# STM32N647 register map
File version: 1.0
CPU: CM55 r0p1, little endian, no MPU, FPU, vendor SysTick, 8 interrupt priority bits
Registers are 32-bit, read-write, reset 0x0 unless marked. A register's access mark holds for its fields unless they carry their own. Offsets are from the block's base; [hi:lo] are bit positions.

## RAMCFG — SRAM configuration controller
Base 0x42023000
Same registers: RAMCFG_S 0x52023000
0x00 AXISRAM1CR — RAMCFG AXISRAM1 control register
  [8] SRAMER — SRAM erase.
0x08 AXISRAM1ISR ro — RAMCFG AXISRAM1 interrupt status register
  [8] SRAMBUSY — SRAM busy with erase operation
0x28 AXISRAM1ERKEYR wo — RAMCFG AXISRAM1 erase key register
  [7:0] ERASEKEY — Erase write protection key
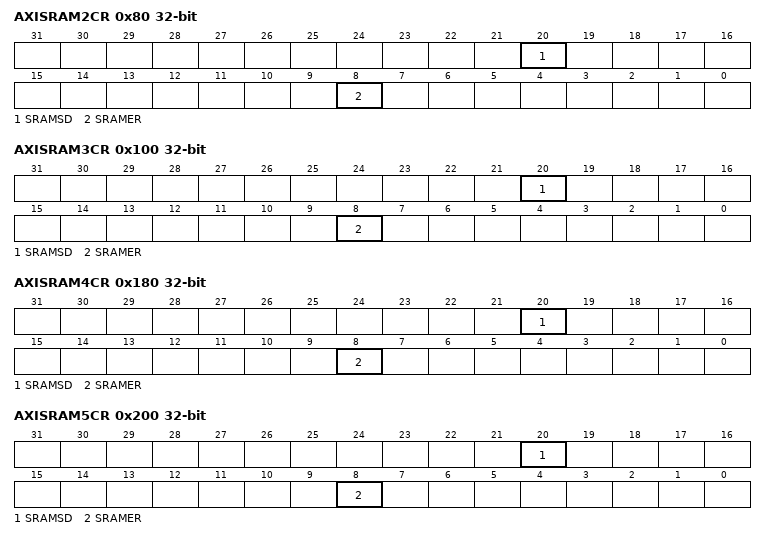
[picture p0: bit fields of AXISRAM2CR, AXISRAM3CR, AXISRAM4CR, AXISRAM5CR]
0x80 AXISRAM2CR — RAMCFG AXISRAM2 control register
  [20] SRAMSD — Shutdown AXISRAMx
  [8] SRAMER — SRAM erase
0x88 AXISRAM2ISR ro — RAMCFG AXISRAM2 interrupt status register
  [8] SRAMBUSY — SRAM busy with erase operation
0xA8 AXISRAM2ERKEYR wo — RAMCFG AXISRAM2 erase key register
  [7:0] ERASEKEY — Erase write protection key
0x100 AXISRAM3CR — RAMCFG AXISRAM3 control register
  [20] SRAMSD — Shutdown AXISRAMx
  [8] SRAMER — SRAM erase
0x108 AXISRAM3ISR ro — RAMCFG AXISRAM3 interrupt status register
  [8] SRAMBUSY — SRAM busy with erase operation
0x128 AXISRAM3ERKEYR wo — RAMCFG AXISRAM3 erase key register
  [7:0] ERASEKEY — Erase write protection key
0x180 AXISRAM4CR — RAMCFG AXISRAM4 control register
  [20] SRAMSD — Shutdown AXISRAMx
  [8] SRAMER — SRAM erase
0x188 AXISRAM4ISR ro — RAMCFG AXISRAM4 interrupt status register
  [8] SRAMBUSY — SRAM busy with erase operation
0x1A8 AXISRAM4ERKEYR wo — RAMCFG AXISRAM4 erase key register
  [7:0] ERASEKEY — Erase write protection key
0x200 AXISRAM5CR — RAMCFG AXISRAM5 control register
  [20] SRAMSD — Shutdown AXISRAMx
  [8] SRAMER — SRAM erase
0x208 AXISRAM5ISR ro — RAMCFG AXISRAM5 interrupt status register
  [8] SRAMBUSY — SRAM busy with erase operation
0x228 AXISRAM5ERKEYR wo — RAMCFG AXISRAM5 erase key register
  [7:0] ERASEKEY — Erase write protection key
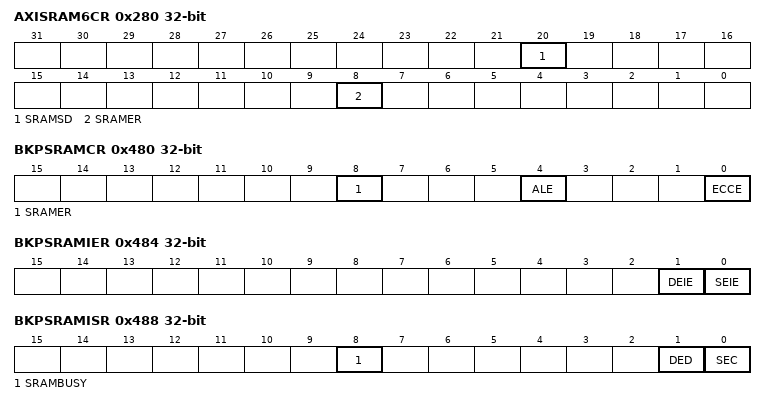
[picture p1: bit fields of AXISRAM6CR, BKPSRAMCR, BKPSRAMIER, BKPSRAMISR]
0x280 AXISRAM6CR — RAMCFG AXISRAM6 control register
  [20] SRAMSD — Shutdown AXISRAMx
  [8] SRAMER — SRAM erase
0x288 AXISRAM6ISR ro — RAMCFG AXISRAM6 interrupt status register
  [8] SRAMBUSY — SRAM busy with erase operation
0x2A8 AXISRAM6ERKEYR wo — RAMCFG AXISRAM6 erase key register
  [7:0] ERASEKEY — Erase write protection key
0x300 AHBSRAM1CR — RAMCFG AHBSRAM1 control register
  [8] SRAMER — SRAM erase
0x308 AHBSRAM1ISR ro — RAMCFG AHBSRAM1 interrupt status register
  [8] SRAMBUSY — SRAM busy with erase operation
0x328 AHBSRAM1ERKEYR wo — RAMCFG AHBSRAM1 erase key register
  [7:0] ERASEKEY — Erase write protection key
0x380 AHBSRAM2CR — RAMCFG AHBSRAM2 control register
  [8] SRAMER — SRAM erase
0x388 AHBSRAM2ISR ro — RAMCFG AHBSRAM2 interrupt status register
  [8] SRAMBUSY — SRAM busy with erase operation
0x3A8 AHBSRAM2ERKEYR wo — RAMCFG AHBSRAM2 erase key register
  [7:0] ERASEKEY — Erase write protection key
0x400 VENCRAMCR — RAMCFG VENCRAM control register
  [8] SRAMER — SRAM erase
0x408 VENCRAMISR ro — RAMCFG VENCRAM interrupt status register
  [8] SRAMBUSY — SRAM busy with erase operation
0x428 VENCRAMERKEYR wo — RAMCFG VENCRAM erase key register
  [7:0] ERASEKEY — Erase write protection key
0x480 BKPSRAMCR — RAMCFG BKPSRAM control register
  [8] SRAMER — SRAM erase
  [4] ALE — Address latch enable
  [0] ECCE — ECC enable
0x484 BKPSRAMIER — RAMCFG BKPSRAM interrupt enable register
  [1] DEIE — ECC double error interrupt enable
  [0] SEIE — ECC single error interrupt enable
0x488 BKPSRAMISR ro — RAMCFG BKPSRAM interrupt status register
  [8] SRAMBUSY — SRAM busy with erase operation
  [1] DED — ECC double-error interrupt enable
  [0] SEC — ECC single error detected
0x48C BKPSRAMESEAR wo — RAMCFG BKPSRAM single error address register
  [10:0] ESEA — ECC single error address
0x490 BKPSRAMEDEAR wo — RAMCFG BKPSRAM double error address register
  [10:0] EDEA — ECC double error address
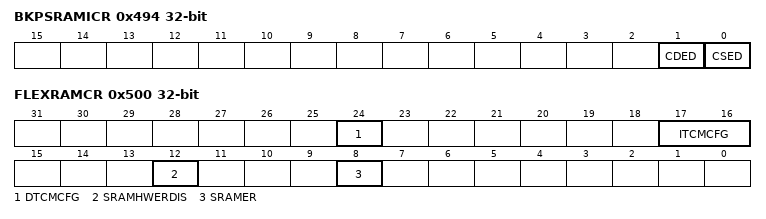
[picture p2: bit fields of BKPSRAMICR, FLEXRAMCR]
0x494 BKPSRAMICR wo — RAMCFG BKPSRAM interrupt clear register
  [1] CDED — Clear ECC double-error interrupt
  [0] CSED — Clear ECC single-error interrupt
0x4A4 BKPSRAMECCKEYR wo — RAMCFG BKPSRAM ECC key register
  [7:0] ECCKEY — ECC write protection key
0x4A8 BKPSRAMERKEYR wo — RAMCFG BKPSRAM erase key register
  [7:0] ERASEKEY — Erase write protection key
0x500 FLEXRAMCR — RAMCFG FLEXRAM control register
  [24] DTCMCFG — Configuration of the FLEXMEM D-TCM extension
  [17:16] ITCMCFG — Configuration of the FLEXMEM I-TCM extension
  [12] SRAMHWERDIS — SRAM hardware erase disable
  [8] SRAMER — SRAM erase
0x508 FLEXRAMISR ro — RAMCFG FLEXRAM interrupt status register
  [8] SRAMBUSY — SRAM busy with erase operation
0x528 FLEXRAMERKEYR wo — RAMCFG FLEXRAM erase key register
  [7:0] ERASEKEY — Erase write protection key
